# FM33A0XXEV register map
File version: 1.0
CPU: SC000, little endian, no MPU, no FPU, 3 interrupt priority bits
Registers are 32-bit, read-write, reset 0x0 unless marked. A register's access mark holds for its fields unless they carry their own. Offsets are from the block's base; [hi:lo] are bit positions; {n}, {i} and the like mark numbered series.

## IWDT — IWDT module information
Base 0x40011400
0x00 SERV — IWDT Serve Register
  [31:0] IWDTSERV wo — IWDTSERV field description
0x04 CFGR reset 0x1 — IWDT Config Register
  [2:0] IWDTOVP — IWDTOVP field description
0x08 CNTR — IWDT Counter Register
  [19:0] IWDTCNT ro — IWDTCNT field description

## WWDT — WWDT module information
Base 0x40011800
0x00 CR — WWDT Control Register
  [7:0] CON wo — CON field description
0x04 CFGR reset 0x3 — WWDT Config Register
  [2:0] CFG — CFG field description
0x08 CNTR — WWDT Counter Register
  [9:0] CNT ro — CNT field description
0x0C IER — WWDT Interrupt Enable Register
  [0] IE — IE field description
0x10 ISR — WWDT Interrupt Status Register
  [0] NOVF — NOVF field description
0x14 PSCR — WWDT Prescaler Register
  [11:0] DIV_CNT ro — DIV_CNT field description

## CDIF — CDIF module information
Base 0x4001E000
0x00 CR reset 0x5 — CDIF Control Register
  [3:0] INTF_EN — INTF_EN field description
0x04 PSCR — CDIF Prescaler Register
  [3:0] PRSC — PRSC field description

## VRTC — VRTC module information
Base 0x4001F800
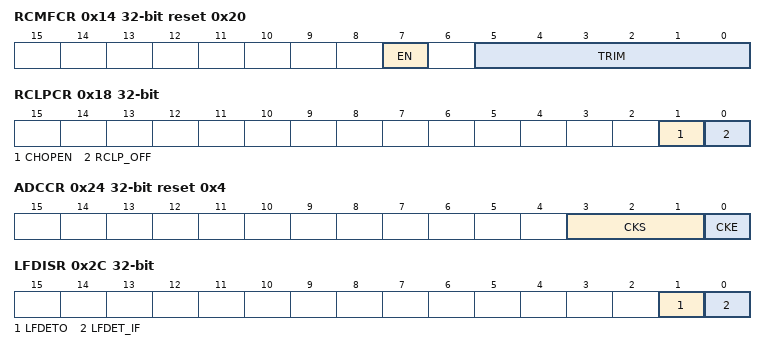
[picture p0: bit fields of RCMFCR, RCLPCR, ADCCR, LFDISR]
0x14 RCMFCR reset 0x20 — RCMF Control Register
  [7] EN — EN field description
  [5:0] TRIM — TRIM field description
0x18 RCLPCR — RCLP Control Register
  [1] CHOPEN — CHOPEN field description
  [0] RCLP_OFF — RCLP_OFF field description
0x1C RCLPTR — RCLP Control Register
  [7:0] RCLP_TRIM — RCLP_TRIM field description
0x20 XTLFCR reset 0x8 — XTLF Control Register
  [3:0] XTLFIPW — XTLFIPW field description
0x24 ADCCR reset 0x4 — ADC Clock Control Register
  [3:1] CKS — CKS field description
  [0] CKE — CKE field description
0x28 LFDIER — LFDET Interrupt Enable Register
  [0] LFDET_IE — LFDET_IE field description
0x2C LFDISR — LFDET Interrupt Status Register
  [1] LFDETO ro — LFDETO field description
  [0] LFDET_IF — LFDET_IF field description

## SVD — SVD module information
Base 0x40012800
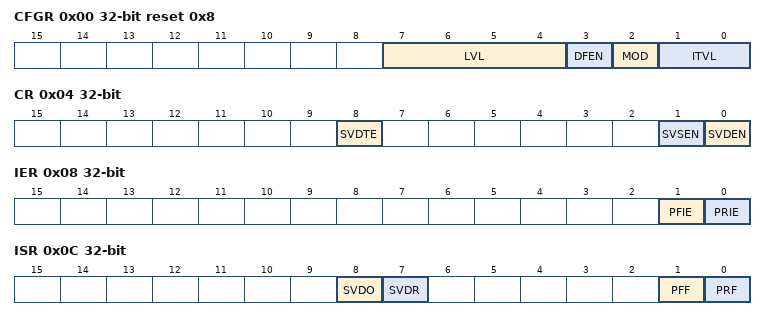
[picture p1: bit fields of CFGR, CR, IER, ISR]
0x00 CFGR reset 0x8 — SVD Config Register
  [7:4] LVL — LVL field description
  [3] DFEN — DFEN field description
  [2] MOD — MOD field description
  [1:0] ITVL — ITVL field description
0x04 CR — SVD Control Register
  [8] SVDTE — SVDTE field description
  [1] SVSEN — SVSEN field description
  [0] SVDEN — SVDEN field description
0x08 IER — SVD Interrupt Enable Register
  [1] PFIE — PFIE field description
  [0] PRIE — PRIE field description
0x0C ISR — SVD Interrupt Status Register
  [8] SVDO ro — SVDO field description
  [7] SVDR ro — SVDR field description
  [1] PFF — PFF field description
  [0] PRF — PRF field description
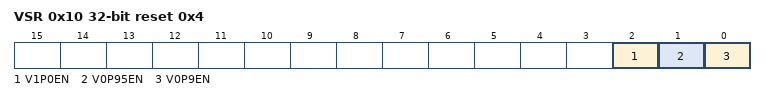
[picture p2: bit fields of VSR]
0x10 VSR reset 0x4 — SVD reference Voltage Select Register
  [2] V1P0EN — V1P0EN field description
  [1] V0P95EN — V0P95EN field description
  [0] V0P9EN — V0P9EN field description

## AES — AES module information
Base 0x40013800
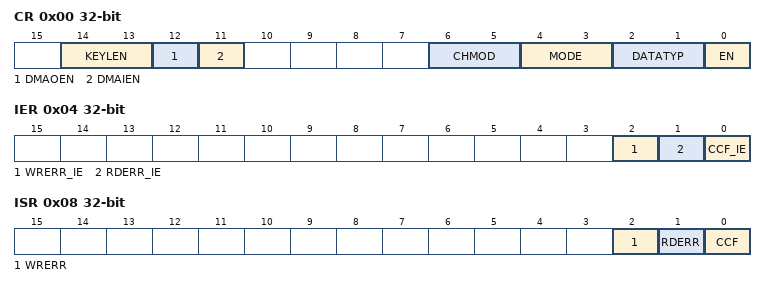
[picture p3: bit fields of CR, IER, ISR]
0x00 CR — AES Control Register
  [14:13] KEYLEN — KEYLEN field description
  [12] DMAOEN — DMAOEN field description
  [11] DMAIEN — DMAIEN field description
  [6:5] CHMOD — CHMOD field description
  [4:3] MODE — MODE field description
  [2:1] DATATYP — DATATYP field description
  [0] EN — EN field description
0x04 IER — AES Interrupt Enable Register
  [2] WRERR_IE — WRERR_IE field description
  [1] RDERR_IE — RDERR_IE field description
  [0] CCF_IE — CCF_IE field description
0x08 ISR — AES Interrupt Status Register
  [2] WRERR — WRERR field description
  [1] RDERR — RDERR field description
  [0] CCF — CCF field description
0x0C DIR — AES Data Input Register
  [31:0] DIN — DIN field description
0x10 DOR — AES Data Output Register
  [31:0] DOUT ro — DOUT field description
{0x14+4i} KEY{i} (i=0..7) — AES Key Register {i}
  [31:0] KEYx wo — KEYx field description
{0x34+4i} IVR{i} (i=0..3) — AES Initial Vector Register {i}
  [31:0] IVRx — IVRx field description
{0x44+4i} H{i} (i=0..3) — AES MultH parameter Register {i}
  [31:0] Hx — Hx field description
